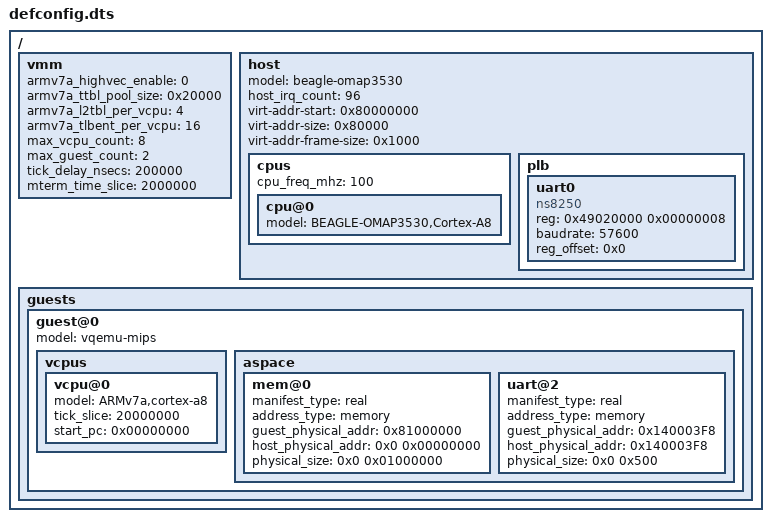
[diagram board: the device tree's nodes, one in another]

/dts-v1/;

/ {
	vmm {
		#address-cells = <1>;
		#size-cells = <0>;
		armv7a_highvec_enable = <0>;
		armv7a_ttbl_pool_size = <0x20000>;
		armv7a_l2tbl_per_vcpu = <4>;
		armv7a_tlbent_per_vcpu = <16>;
		max_vcpu_count = <8>;
		max_guest_count = <2>;
		tick_delay_nsecs = <200000>;
		mterm_time_slice = <2000000>;
	};

	host {
		#address-cells = <2>;
		#size-cells = <1>;
		model = "beagle-omap3530";
		device_type = "host";
		host_irq_count = <96>;
		virt-addr-start = <0x80000000>;
		virt-addr-size = <0x80000>;
		virt-addr-frame-size = <0x1000>; /* 4K minimum page maps */
		
		cpus {
			#address-cells = <1>;
			#size-cells = <0>;
			cpu_freq_mhz = <100>;

			cpu@0 {
				device_type = "cpu";
				model = "BEAGLE-OMAP3530,Cortex-A8";
			};
		};

		plb {
			#address-cells = <1>;
			#size-cells = <0>;
		
			uart0 {
			      device_type = "serial";
			      compatible = "ns8250";
			      reg = <0x49020000 0x00000008>;
			      baudrate = <57600>;
			      reg_offset = <0x0>;
			};

		};


	};
	guests {
		#address-cells = <1>;
		#size-cells = <0>;

		guest@0 {
			#address-cells = <1>;
			#size-cells = <0>;
			model = "vqemu-mips";
			device_type = "guest";

			vcpus {
				#address-cells = <1>;
				#size-cells = <0>;

				vcpu@0 {
					device_type = "vcpu";
					model = "ARMv7a,cortex-a8";
					tick_slice = <20000000>;
					start_pc = <0x00000000>;
				};
			};
			
			aspace {
				#address-cells = <1>;
				#size-cells = <0>;
		
				mem@0 {
					manifest_type = "real";
					address_type = "memory";
					guest_physical_addr = <0x81000000>;
					host_physical_addr = <0x0 0x00000000>;
					physical_size = <0x0 0x01000000>;
					device_type = "memory";
				};

				uart@2 {
					manifest_type = "real";
					address_type = "memory";
					guest_physical_addr = <0x140003F8>;
					host_physical_addr = <0x140003F8>;
					physical_size = <0x0 0x500>;
					device_type = "serial";
				};
			};
		};

	};
};
